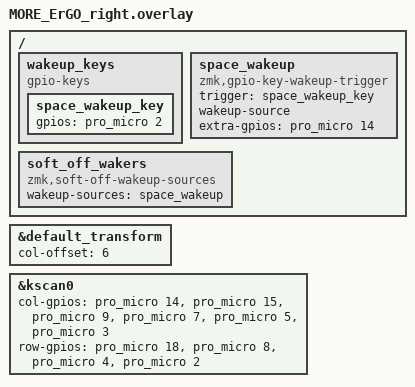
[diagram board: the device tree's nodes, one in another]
#include "MORE_ErGO.dtsi"

&default_transform {
    col-offset = <6>;
};

&kscan0 {
    col-gpios
        = <&pro_micro 14 GPIO_ACTIVE_HIGH>
        , <&pro_micro 15 GPIO_ACTIVE_HIGH>
        , <&pro_micro 9 GPIO_ACTIVE_HIGH>
        , <&pro_micro 7 GPIO_ACTIVE_HIGH>
        , <&pro_micro 5 GPIO_ACTIVE_HIGH>
        , <&pro_micro 3 GPIO_ACTIVE_HIGH>
        ;

    row-gpios
        = <&pro_micro 18 (GPIO_ACTIVE_HIGH | GPIO_PULL_DOWN)>   // row 0
        , <&pro_micro 8  (GPIO_ACTIVE_HIGH | GPIO_PULL_DOWN)>   // row 1 - pin nuevo (puente a D6)
        , <&pro_micro 4  (GPIO_ACTIVE_HIGH | GPIO_PULL_DOWN)>   // row 2
        , <&pro_micro 2  (GPIO_ACTIVE_HIGH | GPIO_PULL_DOWN)>   // row 3
        ;
};
// ── Encender desde soft off SOLO con SPACE (posición 29 = RC(3,6) = col 0 local, fila 3) ──
// Cada mitad se apaga y despierta por separado: esta es la tecla que despierta la mitad derecha.
/ {
    wakeup_keys {
        compatible = "gpio-keys";
        space_wakeup_key: space_wakeup_key {
            gpios = <&pro_micro 2 (GPIO_ACTIVE_HIGH | GPIO_PULL_DOWN)>;   // fila 3 (entrada)
        };
    };

    space_wakeup: space_wakeup {
        compatible = "zmk,gpio-key-wakeup-trigger";
        trigger = <&space_wakeup_key>;
        wakeup-source;
        extra-gpios = <&pro_micro 14 GPIO_ACTIVE_HIGH>;                  // columna 0 de esta mitad (salida)
    };

    soft_off_wakers {
        compatible = "zmk,soft-off-wakeup-sources";
        wakeup-sources = <&space_wakeup>;
    };
};
